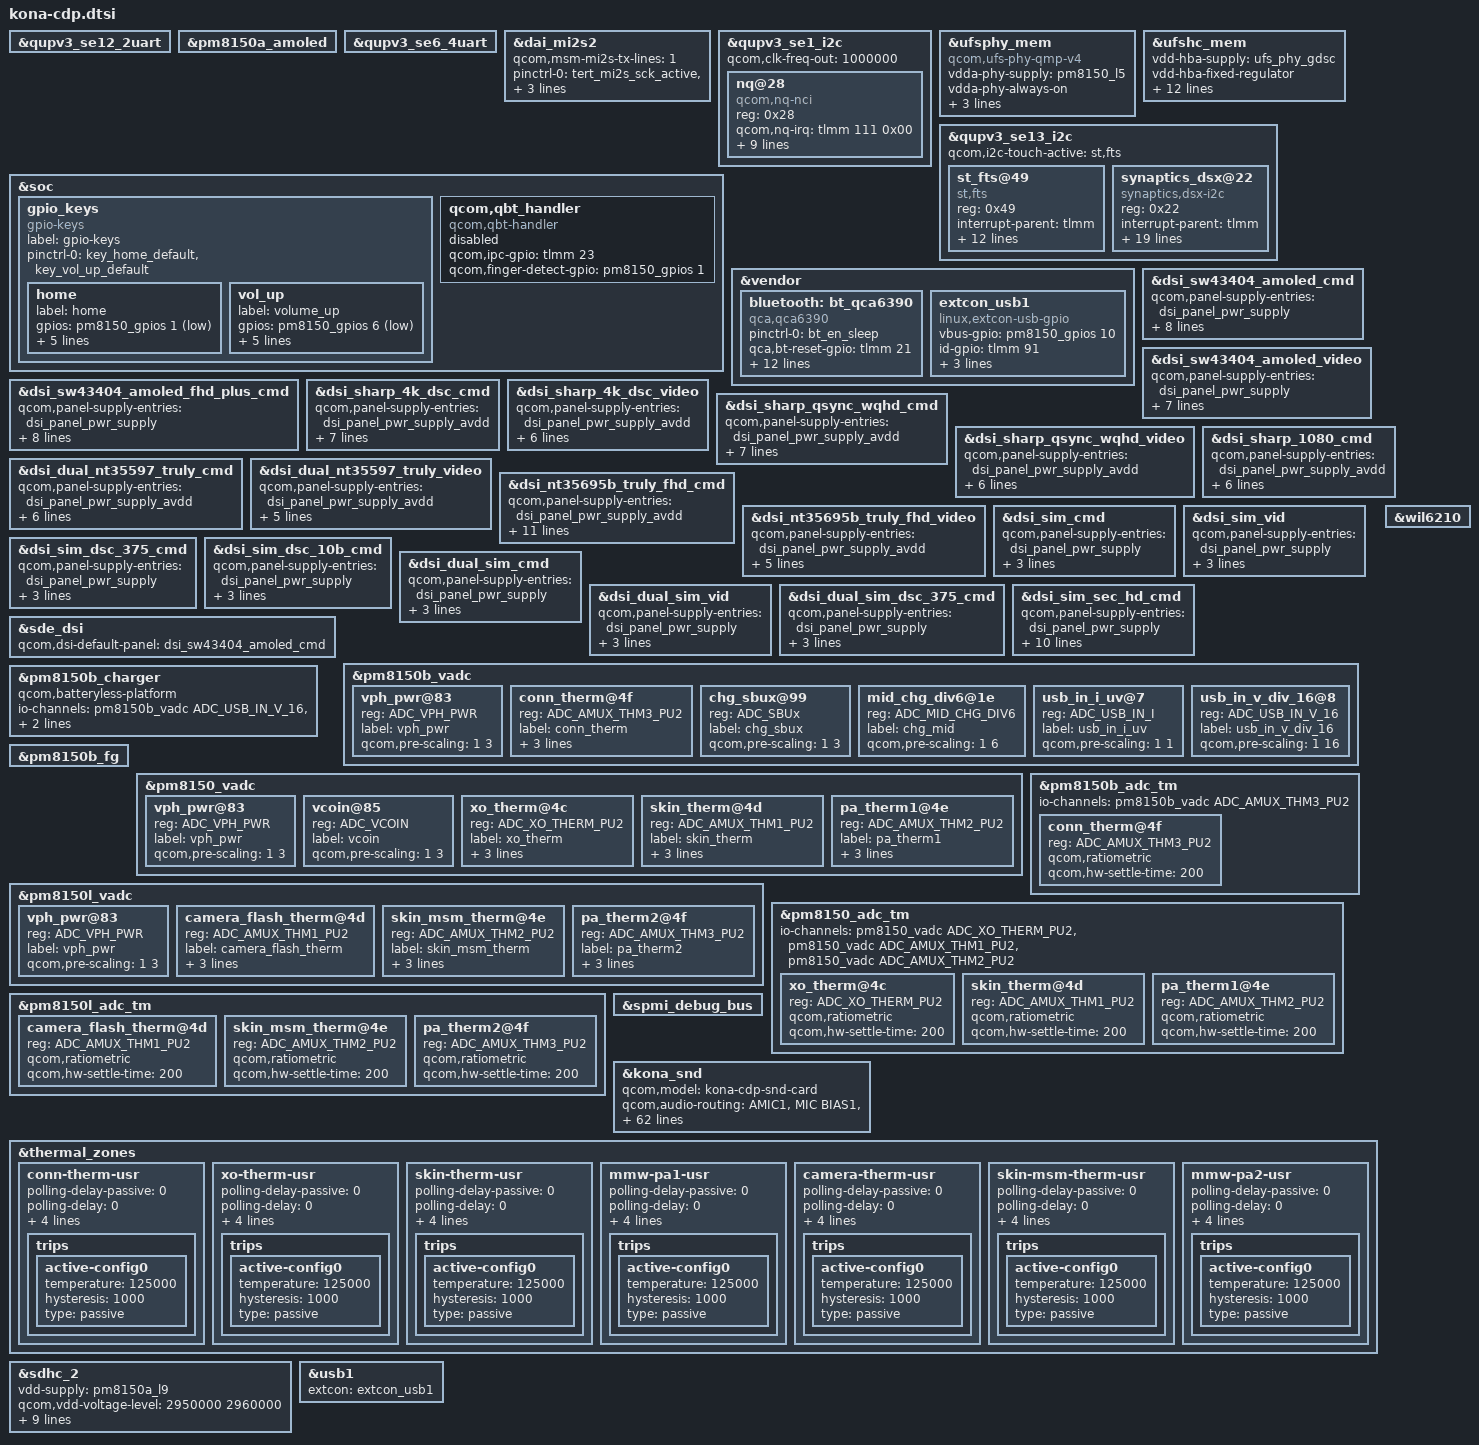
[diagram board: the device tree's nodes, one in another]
#include <dt-bindings/gpio/gpio.h>
#include <dt-bindings/input/input.h>

#include "kona-pmic-overlay.dtsi"
#include "kona-sde-display.dtsi"
#include "camera/kona-camera-sensor-cdp.dtsi"
#include "kona-audio-overlay.dtsi"
#include "kona-thermal-overlay.dtsi"

&qupv3_se12_2uart {
	status = "ok";
};

&pm8150a_amoled {
	status = "ok";
};

&qupv3_se6_4uart {
	status = "ok";
};

&dai_mi2s2 {
	qcom,msm-mi2s-tx-lines = <1>;
	pinctrl-names = "default", "sleep";
	pinctrl-0 = <&tert_mi2s_sck_active &tert_mi2s_ws_active
			&tert_mi2s_sd0_active>;
	pinctrl-1 = <&tert_mi2s_sck_sleep &tert_mi2s_ws_sleep
			&tert_mi2s_sd0_sleep>;
};

&qupv3_se1_i2c {
	status = "ok";
	qcom,clk-freq-out = <1000000>;
	#address-cells = <1>;
	#size-cells = <0>;
	nq@28 {
		compatible = "qcom,nq-nci";
		reg = <0x28>;
		qcom,nq-irq = <&tlmm 111 0x00>;
		qcom,nq-ven = <&tlmm 6 0x00>;
		qcom,nq-firm = <&tlmm 110 0x00>;
		qcom,nq-clkreq = <&tlmm 7 0x00>;
		interrupt-parent = <&tlmm>;
		interrupts = <111 0>;
		interrupt-names = "nfc_irq";
		pinctrl-names = "nfc_active", "nfc_suspend";
		pinctrl-0 = <&nfc_int_active &nfc_enable_active
				&nfc_clk_req_active>;
		pinctrl-1 = <&nfc_int_suspend &nfc_enable_suspend
				&nfc_clk_req_suspend>;
	};
};

&ufsphy_mem {
	compatible = "qcom,ufs-phy-qmp-v4";

	vdda-phy-supply = <&pm8150_l5>;
	vdda-phy-always-on;
	vdda-pll-supply = <&pm8150_l9>;
	vdda-phy-max-microamp = <89900>;
	vdda-pll-max-microamp = <18800>;

	status = "ok";
};

&ufshc_mem {
	vdd-hba-supply = <&ufs_phy_gdsc>;
	vdd-hba-fixed-regulator;
	vcc-supply = <&pm8150_l17>;
	vcc-voltage-level = <2504000 2950000>;
	vcc-low-voltage-sup;
	vccq-supply = <&pm8150_l6>;
	vccq2-supply = <&pm8150_s4>;
	vccq-max-microamp = <800000>;
	vcc-max-microamp = <800000>;
	vccq2-max-microamp = <800000>;

	qcom,vddp-ref-clk-supply = <&pm8150_l6>;
	qcom,vddp-ref-clk-max-microamp = <100>;
	qcom,vccq-parent-supply = <&pm8150a_s8>;
	qcom,vccq-parent-max-microamp = <210000>;

	status = "ok";
};

&soc {
	gpio_keys {
		compatible = "gpio-keys";
		label = "gpio-keys";

		pinctrl-names = "default";
		pinctrl-0 = <&key_home_default
			     &key_vol_up_default>;

		home {
			label = "home";
			gpios = <&pm8150_gpios 1 GPIO_ACTIVE_LOW>;
			linux,input-type = <1>;
			linux,code = <KEY_HOME>;
			gpio-key,wakeup;
			debounce-interval = <15>;
			linux,can-disable;
		};

		vol_up {
			label = "volume_up";
			gpios = <&pm8150_gpios 6 GPIO_ACTIVE_LOW>;
			linux,input-type = <1>;
			linux,code = <KEY_VOLUMEUP>;
			gpio-key,wakeup;
			debounce-interval = <15>;
			linux,can-disable;
		};
	};

	qcom,qbt_handler {
		compatible = "qcom,qbt-handler";
		qcom,ipc-gpio = <&tlmm 23 0>;
		qcom,finger-detect-gpio = <&pm8150_gpios 1 0>;
		status = "disabled";
	};
};

&qupv3_se13_i2c {
	#address-cells = <1>;
	#size-cells = <0>;

	status = "ok";
	qcom,i2c-touch-active = "st,fts";

	st_fts@49 {
		compatible = "st,fts";
		reg = <0x49>;
		interrupt-parent = <&tlmm>;
		interrupts = <39 0x2008>;
		vdd-supply = <&pm8150a_l1>;
		avdd-supply = <&pm8150_l13>;
		pinctrl-names = "pmx_ts_active", "pmx_ts_suspend";
		pinctrl-0 = <&ts_active>;
		pinctrl-1 = <&ts_int_suspend &ts_reset_suspend>;
		st,irq-gpio = <&tlmm 39 0x2008>;
		st,reset-gpio = <&tlmm 38 0x00>;
		st,regulator_dvdd = "vdd";
		st,regulator_avdd = "avdd";
		panel = <&dsi_sw43404_amoled_cmd &dsi_sw43404_amoled_video
			 &dsi_sw43404_amoled_fhd_plus_cmd>;
	};

	synaptics_dsx@22 {
		compatible = "synaptics,dsx-i2c";
		reg = <0x22>;
		interrupt-parent = <&tlmm>;
		interrupts = <39 0x2008>;
		vdd-supply = <&pm8150a_l1>;
		avdd-supply = <&pm8150_l13>;
		pinctrl-names = "pmx_ts_active", "pmx_ts_suspend",
				"pmx_ts_release";
		pinctrl-0 = <&ts_active>;
		pinctrl-1 = <&ts_int_suspend &ts_reset_suspend>;
		pinctrl-2 = <&pmx_ts_release>;
		synaptics,pwr-reg-name = "avdd";
		synaptics,bus-reg-name = "vdd";
		synaptics,ub-i2c-addr = <0x22>;
		synaptics,max-y-for-2d = <1859>;
		synaptics,irq-gpio = <&tlmm 39 0x2008>;
		synaptics,reset-gpio = <&tlmm 38 0x0>;
		synaptics,irq-on-state = <0>;
		synaptics,power-delay-ms = <200>;
		synaptics,reset-delay-ms = <200>;
		synaptics,reset-on-state = <0>;
		synaptics,reset-active-ms = <20>;

		panel = <&dsi_sharp_qsync_wqhd_cmd &dsi_sharp_qsync_wqhd_video>;
	};
};

&vendor {
	bluetooth: bt_qca6390 {
		compatible = "qca,qca6390";
		pinctrl-names = "default";
		pinctrl-0 = <&bt_en_sleep>;
		qca,bt-reset-gpio = <&tlmm 21 0>; /* BT_EN */
		qca,bt-sw-ctrl-gpio = <&tlmm 124 0>; /* SW_CTRL */
		qca,bt-vdd-aon-supply = <&pm8150_s6>;
		qca,bt-vdd-dig-supply = <&pm8009_s2>;
		qca,bt-vdd-rfa1-supply = <&pm8150_s5>;
		qca,bt-vdd-rfa2-supply = <&pm8150a_s8>;
		qca,bt-vdd-asd-supply = <&pm8150_l16>;

		qca,bt-vdd-aon-voltage-level = <950000 950000>;
		qca,bt-vdd-dig-voltage-level = <950000 952000>;
		qca,bt-vdd-rfa1-voltage-level = <1900000 1900000>;
		qca,bt-vdd-rfa2-voltage-level = <1350000 1350000>;
		qca,bt-vdd-asd-voltage-level = <3024000 3304000>;

		qca,bt-vdd-asd-current-level = <10000>;
	};

	extcon_usb1: extcon_usb1 {
		compatible = "linux,extcon-usb-gpio";
		vbus-gpio = <&pm8150_gpios 10 GPIO_ACTIVE_HIGH>;
		id-gpio = <&tlmm 91 GPIO_ACTIVE_HIGH>;
		vbus-out-gpio = <&pm8150_gpios 9 GPIO_ACTIVE_HIGH>;

		pinctrl-names = "default";
		pinctrl-0 = <&usb2_vbus_det_default
			     &usb2_id_det_default
			     &usb2_vbus_boost_default>;
	};
};

&dsi_sw43404_amoled_cmd {
	qcom,panel-supply-entries = <&dsi_panel_pwr_supply>;
	qcom,mdss-dsi-bl-pmic-control-type = "bl_ctrl_dcs";
	qcom,mdss-dsi-bl-min-level = <1>;
	qcom,mdss-dsi-bl-max-level = <1023>;
	qcom,mdss-brightness-max-level = <255>;
	qcom,platform-te-gpio = <&tlmm 66 0>;
	qcom,platform-reset-gpio = <&tlmm 75 0>;
	qcom,mdss-dsi-panel-test-pin = <&tlmm 46 0>;
};

&dsi_sw43404_amoled_video {
	qcom,panel-supply-entries = <&dsi_panel_pwr_supply>;
	qcom,mdss-dsi-bl-pmic-control-type = "bl_ctrl_dcs";
	qcom,mdss-dsi-bl-min-level = <1>;
	qcom,mdss-dsi-bl-max-level = <1023>;
	qcom,mdss-brightness-max-level = <255>;
	qcom,platform-reset-gpio = <&tlmm 75 0>;
	qcom,mdss-dsi-panel-test-pin = <&tlmm 46 0>;
};

&dsi_sw43404_amoled_fhd_plus_cmd {
	qcom,panel-supply-entries = <&dsi_panel_pwr_supply>;
	qcom,mdss-dsi-bl-pmic-control-type = "bl_ctrl_dcs";
	qcom,mdss-dsi-bl-min-level = <1>;
	qcom,mdss-dsi-bl-max-level = <1023>;
	qcom,mdss-brightness-max-level = <255>;
	qcom,platform-te-gpio = <&tlmm 66 0>;
	qcom,platform-reset-gpio = <&tlmm 75 0>;
	qcom,mdss-dsi-panel-test-pin = <&tlmm 46 0>;
};

&dsi_sharp_4k_dsc_cmd {
	qcom,panel-supply-entries = <&dsi_panel_pwr_supply_avdd>;
	qcom,mdss-dsi-bl-pmic-control-type = "bl_ctrl_external";
	qcom,mdss-dsi-bl-min-level = <1>;
	qcom,mdss-dsi-bl-max-level = <4095>;
	qcom,platform-te-gpio = <&tlmm 66 0>;
	qcom,platform-reset-gpio = <&tlmm 75 0>;
	qcom,platform-en-gpio = <&tlmm 60 0>;
};

&dsi_sharp_4k_dsc_video {
	qcom,panel-supply-entries = <&dsi_panel_pwr_supply_avdd>;
	qcom,mdss-dsi-bl-pmic-control-type = "bl_ctrl_external";
	qcom,mdss-dsi-bl-min-level = <1>;
	qcom,mdss-dsi-bl-max-level = <4095>;
	qcom,platform-reset-gpio = <&tlmm 75 0>;
	qcom,platform-en-gpio = <&tlmm 60 0>;
};

&dsi_sharp_qsync_wqhd_cmd {
	qcom,panel-supply-entries = <&dsi_panel_pwr_supply_avdd>;
	qcom,mdss-dsi-bl-pmic-control-type = "bl_ctrl_external";
	qcom,mdss-dsi-bl-min-level = <1>;
	qcom,mdss-dsi-bl-max-level = <4095>;
	qcom,platform-te-gpio = <&tlmm 66 0>;
	qcom,platform-reset-gpio = <&tlmm 75 0>;
	qcom,platform-en-gpio = <&tlmm 60 0>;
};

&dsi_sharp_qsync_wqhd_video {
	qcom,panel-supply-entries = <&dsi_panel_pwr_supply_avdd>;
	qcom,mdss-dsi-bl-pmic-control-type = "bl_ctrl_external";
	qcom,mdss-dsi-bl-min-level = <1>;
	qcom,mdss-dsi-bl-max-level = <4095>;
	qcom,platform-reset-gpio = <&tlmm 75 0>;
	qcom,platform-en-gpio = <&tlmm 60 0>;
};

&dsi_sharp_1080_cmd {
	qcom,panel-supply-entries = <&dsi_panel_pwr_supply_avdd>;
	qcom,mdss-dsi-bl-pmic-control-type = "bl_ctrl_external";
	qcom,mdss-dsi-bl-min-level = <1>;
	qcom,mdss-dsi-bl-max-level = <4095>;
	qcom,platform-te-gpio = <&tlmm 66 0>;
	qcom,platform-reset-gpio = <&tlmm 75 0>;
};

&dsi_dual_nt35597_truly_cmd {
	qcom,panel-supply-entries = <&dsi_panel_pwr_supply_avdd>;
	qcom,mdss-dsi-bl-pmic-control-type = "bl_ctrl_external";
	qcom,mdss-dsi-bl-min-level = <1>;
	qcom,mdss-dsi-bl-max-level = <4095>;
	qcom,platform-te-gpio = <&tlmm 66 0>;
	qcom,platform-reset-gpio = <&tlmm 75 0>;
};

&dsi_dual_nt35597_truly_video {
	qcom,panel-supply-entries = <&dsi_panel_pwr_supply_avdd>;
	qcom,mdss-dsi-bl-pmic-control-type = "bl_ctrl_external";
	qcom,mdss-dsi-bl-min-level = <1>;
	qcom,mdss-dsi-bl-max-level = <4095>;
	qcom,platform-reset-gpio = <&tlmm 75 0>;
};

&dsi_nt35695b_truly_fhd_cmd {
	qcom,panel-supply-entries = <&dsi_panel_pwr_supply_avdd>;
	qcom,panel-sec-supply-entries = <&dsi_panel_pwr_supply_avdd>;
	qcom,mdss-dsi-bl-pmic-control-type = "bl_ctrl_external";
	qcom,mdss-dsi-sec-bl-pmic-control-type = "bl_ctrl_external";
	qcom,mdss-dsi-bl-min-level = <1>;
	qcom,mdss-dsi-bl-max-level = <4095>;
	qcom,platform-te-gpio = <&tlmm 66 0>;
	qcom,platform-reset-gpio = <&tlmm 75 0>;
	qcom,platform-sec-reset-gpio = <&tlmm 128 0>;
};

&dsi_nt35695b_truly_fhd_video {
	qcom,panel-supply-entries = <&dsi_panel_pwr_supply_avdd>;
	qcom,mdss-dsi-bl-pmic-control-type = "bl_ctrl_external";
	qcom,mdss-dsi-bl-min-level = <1>;
	qcom,mdss-dsi-bl-max-level = <4095>;
	qcom,platform-reset-gpio = <&tlmm 75 0>;
};

&dsi_sim_cmd {
	qcom,panel-supply-entries = <&dsi_panel_pwr_supply>;
	qcom,mdss-dsi-bl-pmic-control-type = "bl_ctrl_dcs";
	qcom,platform-reset-gpio = <&tlmm 75 0>;
};

&dsi_sim_vid {
	qcom,panel-supply-entries = <&dsi_panel_pwr_supply>;
	qcom,mdss-dsi-bl-pmic-control-type = "bl_ctrl_dcs";
	qcom,platform-reset-gpio = <&tlmm 75 0>;
};

&dsi_sim_dsc_375_cmd {
	qcom,panel-supply-entries = <&dsi_panel_pwr_supply>;
	qcom,mdss-dsi-bl-pmic-control-type = "bl_ctrl_dcs";
	qcom,platform-reset-gpio = <&tlmm 75 0>;
};

&dsi_sim_dsc_10b_cmd {
	qcom,panel-supply-entries = <&dsi_panel_pwr_supply>;
	qcom,mdss-dsi-bl-pmic-control-type = "bl_ctrl_dcs";
	qcom,platform-reset-gpio = <&tlmm 75 0>;
};

&dsi_dual_sim_cmd {
	qcom,panel-supply-entries = <&dsi_panel_pwr_supply>;
	qcom,mdss-dsi-bl-pmic-control-type = "bl_ctrl_dcs";
	qcom,platform-reset-gpio = <&tlmm 75 0>;
};

&dsi_dual_sim_vid {
	qcom,panel-supply-entries = <&dsi_panel_pwr_supply>;
	qcom,mdss-dsi-bl-pmic-control-type = "bl_ctrl_dcs";
	qcom,platform-reset-gpio = <&tlmm 75 0>;
};

&dsi_dual_sim_dsc_375_cmd {
	qcom,panel-supply-entries = <&dsi_panel_pwr_supply>;
	qcom,mdss-dsi-bl-pmic-control-type = "bl_ctrl_dcs";
	qcom,platform-reset-gpio = <&tlmm 75 0>;
};

&dsi_sim_sec_hd_cmd {
	qcom,panel-supply-entries = <&dsi_panel_pwr_supply>;
	qcom,panel-sec-supply-entries = <&dsi_panel_pwr_supply>;
	qcom,mdss-dsi-bl-pmic-control-type = "bl_ctrl_dcs";
	qcom,mdss-dsi-sec-bl-pmic-control-type = "bl_ctrl_dcs";
	qcom,mdss-dsi-bl-min-level = <1>;
	qcom,mdss-dsi-bl-max-level = <1023>;
	qcom,platform-reset-gpio = <&tlmm 75 0>;
	qcom,platform-sec-reset-gpio = <&tlmm 128 0>;
};

&sde_dsi {
	qcom,dsi-default-panel = <&dsi_sw43404_amoled_cmd>;
};

&pm8150b_vadc {
	#address-cells = <1>;
	#size-cells = <0>;

	vph_pwr@83 {
		reg = <ADC_VPH_PWR>;
		label = "vph_pwr";
		qcom,pre-scaling = <1 3>;
	};

	conn_therm@4f {
		reg = <ADC_AMUX_THM3_PU2>;
		label = "conn_therm";
		qcom,ratiometric;
		qcom,hw-settle-time = <200>;
		qcom,pre-scaling = <1 1>;
	};

	chg_sbux@99 {
		reg = <ADC_SBUx>;
		label = "chg_sbux";
		qcom,pre-scaling = <1 3>;
	};

	mid_chg_div6@1e {
		reg = <ADC_MID_CHG_DIV6>;
		label = "chg_mid";
		qcom,pre-scaling = <1 6>;
	};

	usb_in_i_uv@7 {
		reg = <ADC_USB_IN_I>;
		label = "usb_in_i_uv";
		qcom,pre-scaling = <1 1>;
	};

	usb_in_v_div_16@8 {
		reg = <ADC_USB_IN_V_16>;
		label = "usb_in_v_div_16";
		qcom,pre-scaling = <1 16>;
	};
};

&pm8150b_charger {
	status = "ok";
	qcom,batteryless-platform;
	io-channels = <&pm8150b_vadc ADC_USB_IN_V_16>,
		      <&pm8150b_vadc ADC_USB_IN_I>,
		      <&pm8150b_vadc ADC_CHG_TEMP>;
	io-channel-names = "usb_in_voltage",
			   "usb_in_current",
			   "chg_temp";
};

&pm8150b_fg {
	status = "ok";
};

&pm8150_vadc {
	#address-cells = <1>;
	#size-cells = <0>;

	vph_pwr@83 {
		reg = <ADC_VPH_PWR>;
		label = "vph_pwr";
		qcom,pre-scaling = <1 3>;
	};

	vcoin@85 {
		reg = <ADC_VCOIN>;
		label = "vcoin";
		qcom,pre-scaling = <1 3>;
	};

	xo_therm@4c {
		reg = <ADC_XO_THERM_PU2>;
		label = "xo_therm";
		qcom,ratiometric;
		qcom,hw-settle-time = <200>;
		qcom,pre-scaling = <1 1>;
	};

	skin_therm@4d {
		reg = <ADC_AMUX_THM1_PU2>;
		label = "skin_therm";
		qcom,ratiometric;
		qcom,hw-settle-time = <200>;
		qcom,pre-scaling = <1 1>;
	};

	pa_therm1@4e {
		reg = <ADC_AMUX_THM2_PU2>;
		label = "pa_therm1";
		qcom,ratiometric;
		qcom,hw-settle-time = <200>;
		qcom,pre-scaling = <1 1>;
	};
};

&pm8150l_vadc {
	#address-cells = <1>;
	#size-cells = <0>;

	vph_pwr@83 {
		reg = <ADC_VPH_PWR>;
		label = "vph_pwr";
		qcom,pre-scaling = <1 3>;
	};

	camera_flash_therm@4d {
		reg = <ADC_AMUX_THM1_PU2>;
		label = "camera_flash_therm";
		qcom,ratiometric;
		qcom,hw-settle-time = <200>;
		qcom,pre-scaling = <1 1>;
	};

	skin_msm_therm@4e {
		reg = <ADC_AMUX_THM2_PU2>;
		label = "skin_msm_therm";
		qcom,ratiometric;
		qcom,hw-settle-time = <200>;
		qcom,pre-scaling = <1 1>;
	};

	pa_therm2@4f {
		reg = <ADC_AMUX_THM3_PU2>;
		label = "pa_therm2";
		qcom,ratiometric;
		qcom,hw-settle-time = <200>;
		qcom,pre-scaling = <1 1>;
	};
};

&pm8150b_adc_tm {
	#address-cells = <1>;
	#size-cells = <0>;

	io-channels = <&pm8150b_vadc ADC_AMUX_THM3_PU2>;

	conn_therm@4f {
		reg = <ADC_AMUX_THM3_PU2>;
		qcom,ratiometric;
		qcom,hw-settle-time = <200>;
	};
};

&pm8150_adc_tm {
	#address-cells = <1>;
	#size-cells = <0>;

	io-channels = <&pm8150_vadc ADC_XO_THERM_PU2>,
			<&pm8150_vadc ADC_AMUX_THM1_PU2>,
			<&pm8150_vadc ADC_AMUX_THM2_PU2>;

	xo_therm@4c {
		reg = <ADC_XO_THERM_PU2>;
		qcom,ratiometric;
		qcom,hw-settle-time = <200>;
	};

	skin_therm@4d {
		reg = <ADC_AMUX_THM1_PU2>;
		qcom,ratiometric;
		qcom,hw-settle-time = <200>;
	};

	pa_therm1@4e {
		reg = <ADC_AMUX_THM2_PU2>;
		qcom,ratiometric;
		qcom,hw-settle-time = <200>;
	};
};

&pm8150l_adc_tm {
	#address-cells = <1>;
	#size-cells = <0>;

	camera_flash_therm@4d {
		reg = <ADC_AMUX_THM1_PU2>;
		qcom,ratiometric;
		qcom,hw-settle-time = <200>;
	};

	skin_msm_therm@4e {
		reg = <ADC_AMUX_THM2_PU2>;
		qcom,ratiometric;
		qcom,hw-settle-time = <200>;
	};

	pa_therm2@4f {
		reg = <ADC_AMUX_THM3_PU2>;
		qcom,ratiometric;
		qcom,hw-settle-time = <200>;
	};
};

&spmi_debug_bus {
	status = "ok";
};

&kona_snd {
	qcom,model = "kona-cdp-snd-card";
	qcom,audio-routing =
		"AMIC1", "MIC BIAS1",
		"MIC BIAS1", "Analog Mic1",
		"AMIC2", "MIC BIAS2",
		"MIC BIAS2", "Analog Mic2",
		"AMIC3", "MIC BIAS3",
		"MIC BIAS3", "Analog Mic3",
		"AMIC4", "MIC BIAS3",
		"MIC BIAS3", "Analog Mic4",
		"AMIC5", "MIC BIAS4",
		"MIC BIAS4", "Analog Mic5",
		"TX DMIC0", "MIC BIAS3",
		"MIC BIAS3", "Digital Mic0",
		"TX DMIC1", "MIC BIAS3",
		"MIC BIAS3", "Digital Mic1",
		"TX DMIC2", "MIC BIAS1",
		"MIC BIAS1", "Digital Mic2",
		"TX DMIC3", "MIC BIAS1",
		"MIC BIAS1", "Digital Mic3",
		"TX DMIC4", "MIC BIAS4",
		"MIC BIAS4", "Digital Mic4",
		"TX DMIC5", "MIC BIAS4",
		"MIC BIAS4", "Digital Mic5",
		"DMIC1", "MIC BIAS3",
		"MIC BIAS3", "Digital Mic0",
		"DMIC2", "MIC BIAS3",
		"MIC BIAS3", "Digital Mic1",
		"DMIC3", "MIC BIAS1",
		"MIC BIAS1", "Digital Mic2",
		"DMIC4", "MIC BIAS1",
		"MIC BIAS1", "Digital Mic3",
		"DMIC5", "MIC BIAS4",
		"MIC BIAS4", "Digital Mic4",
		"DMIC6", "MIC BIAS4",
		"MIC BIAS4", "Digital Mic5",
		"DMIC7", "MIC BIAS3",
		"MIC BIAS3", "Digital Mic6",
		"DMIC8", "MIC BIAS3",
		"MIC BIAS3", "Digital Mic7",
		"IN1_HPHL", "HPHL_OUT",
		"IN2_HPHR", "HPHR_OUT",
		"IN3_AUX", "AUX_OUT",
		"TX SWR_ADC0", "ADC1_OUTPUT",
		"TX SWR_ADC1", "ADC2_OUTPUT",
		"TX SWR_ADC2", "ADC3_OUTPUT",
		"TX SWR_ADC3", "ADC4_OUTPUT",
		"TX SWR_DMIC0", "DMIC1_OUTPUT",
		"TX SWR_DMIC1", "DMIC2_OUTPUT",
		"TX SWR_DMIC2", "DMIC3_OUTPUT",
		"TX SWR_DMIC3", "DMIC4_OUTPUT",
		"TX SWR_DMIC4", "DMIC5_OUTPUT",
		"TX SWR_DMIC5", "DMIC6_OUTPUT",
		"TX SWR_DMIC6", "DMIC7_OUTPUT",
		"TX SWR_DMIC7", "DMIC8_OUTPUT",
		"WSA SRC0_INP", "SRC0",
		"WSA_TX DEC0_INP", "TX DEC0 MUX",
		"WSA_TX DEC1_INP", "TX DEC1 MUX",
		"RX_TX DEC0_INP", "TX DEC0 MUX",
		"RX_TX DEC1_INP", "TX DEC1 MUX",
		"RX_TX DEC2_INP", "TX DEC2 MUX",
		"RX_TX DEC3_INP", "TX DEC3 MUX",
		"SpkrLeft IN", "WSA_SPK1 OUT",
		"SpkrRight IN", "WSA_SPK2 OUT",
		"VA_AIF1 CAP", "VA_SWR_CLK",
		"VA_AIF2 CAP", "VA_SWR_CLK",
		"VA_AIF3 CAP", "VA_SWR_CLK",
		"VA MIC BIAS3", "Digital Mic0",
		"VA MIC BIAS3", "Digital Mic1",
		"VA MIC BIAS1", "Digital Mic2",
		"VA MIC BIAS1", "Digital Mic3",
		"VA MIC BIAS4", "Digital Mic4",
		"VA MIC BIAS4", "Digital Mic5",
		"VA DMIC0", "VA MIC BIAS3",
		"VA DMIC1", "VA MIC BIAS3",
		"VA DMIC2", "VA MIC BIAS1",
		"VA DMIC3", "VA MIC BIAS1",
		"VA DMIC4", "VA MIC BIAS4",
		"VA DMIC5", "VA MIC BIAS4",
		"VA SWR_ADC0", "VA_SWR_CLK",
		"VA SWR_ADC1", "VA_SWR_CLK",
		"VA SWR_ADC2", "VA_SWR_CLK",
		"VA SWR_ADC3", "VA_SWR_CLK",
		"VA SWR_MIC0", "VA_SWR_CLK",
		"VA SWR_MIC1", "VA_SWR_CLK",
		"VA SWR_MIC2", "VA_SWR_CLK",
		"VA SWR_MIC3", "VA_SWR_CLK",
		"VA SWR_MIC4", "VA_SWR_CLK",
		"VA SWR_MIC5", "VA_SWR_CLK",
		"VA SWR_MIC6", "VA_SWR_CLK",
		"VA SWR_MIC7", "VA_SWR_CLK",
		"VA SWR_ADC0", "ADC1_OUTPUT",
		"VA SWR_ADC1", "ADC2_OUTPUT",
		"VA SWR_ADC2", "ADC3_OUTPUT",
		"VA SWR_ADC3", "ADC4_OUTPUT",
		"VA SWR_MIC0", "DMIC1_OUTPUT",
		"VA SWR_MIC1", "DMIC2_OUTPUT",
		"VA SWR_MIC2", "DMIC3_OUTPUT",
		"VA SWR_MIC3", "DMIC4_OUTPUT",
		"VA SWR_MIC4", "DMIC5_OUTPUT",
		"VA SWR_MIC5", "DMIC6_OUTPUT",
		"VA SWR_MIC6", "DMIC7_OUTPUT",
		"VA SWR_MIC7", "DMIC8_OUTPUT";
};

&thermal_zones {
	conn-therm-usr {
		polling-delay-passive = <0>;
		polling-delay = <0>;
		thermal-governor = "user_space";
		thermal-sensors = <&pm8150b_adc_tm ADC_AMUX_THM3_PU2>;
		wake-capable-sensor;
		trips {
			active-config0 {
				temperature = <125000>;
				hysteresis = <1000>;
				type = "passive";
			};
		};
	};

	xo-therm-usr {
		polling-delay-passive = <0>;
		polling-delay = <0>;
		thermal-governor = "user_space";
		thermal-sensors = <&pm8150_adc_tm ADC_XO_THERM_PU2>;
		wake-capable-sensor;
		trips {
			active-config0 {
				temperature = <125000>;
				hysteresis = <1000>;
				type = "passive";
			};
		};
	};

	skin-therm-usr {
		polling-delay-passive = <0>;
		polling-delay = <0>;
		thermal-governor = "user_space";
		thermal-sensors = <&pm8150_adc_tm ADC_AMUX_THM1_PU2>;
		wake-capable-sensor;
		trips {
			active-config0 {
				temperature = <125000>;
				hysteresis = <1000>;
				type = "passive";
			};
		};
	};

	mmw-pa1-usr {
		polling-delay-passive = <0>;
		polling-delay = <0>;
		thermal-governor = "user_space";
		thermal-sensors = <&pm8150_adc_tm ADC_AMUX_THM2_PU2>;
		wake-capable-sensor;
		trips {
			active-config0 {
				temperature = <125000>;
				hysteresis = <1000>;
				type = "passive";
			};
		};
	};

	camera-therm-usr {
		polling-delay-passive = <0>;
		polling-delay = <0>;
		thermal-governor = "user_space";
		thermal-sensors = <&pm8150l_adc_tm ADC_AMUX_THM1_PU2>;
		wake-capable-sensor;
		trips {
			active-config0 {
				temperature = <125000>;
				hysteresis = <1000>;
				type = "passive";
			};
		};
	};

	skin-msm-therm-usr {
		polling-delay-passive = <0>;
		polling-delay = <0>;
		thermal-governor = "user_space";
		thermal-sensors = <&pm8150l_adc_tm ADC_AMUX_THM2_PU2>;
		wake-capable-sensor;
		trips {
			active-config0 {
				temperature = <125000>;
				hysteresis = <1000>;
				type = "passive";
			};
		};
	};

	mmw-pa2-usr {
		polling-delay-passive = <0>;
		polling-delay = <0>;
		thermal-governor = "user_space";
		thermal-sensors = <&pm8150l_adc_tm ADC_AMUX_THM3_PU2>;
		wake-capable-sensor;
		trips {
			active-config0 {
				temperature = <125000>;
				hysteresis = <1000>;
				type = "passive";
			};
		};
	};
};

&sdhc_2 {
	vdd-supply = <&pm8150a_l9>;
	qcom,vdd-voltage-level = <2950000 2960000>;
	qcom,vdd-current-level = <200 800000>;

	vdd-io-supply = <&pm8150a_l6>;
	qcom,vdd-io-voltage-level = <1808000 2960000>;
	qcom,vdd-io-current-level = <200 22000>;

	pinctrl-names = "active", "sleep";
	pinctrl-0 = <&sdc2_clk_on  &sdc2_cmd_on &sdc2_data_on &storage_cd>;
	pinctrl-1 = <&sdc2_clk_off &sdc2_cmd_off &sdc2_data_off &storage_cd>;

	cd-gpios = <&tlmm 77 GPIO_ACTIVE_LOW>;

	status = "ok";
};

&usb1 {
	extcon = <&extcon_usb1>;
};

&wil6210 {
	status = "ok";
};
